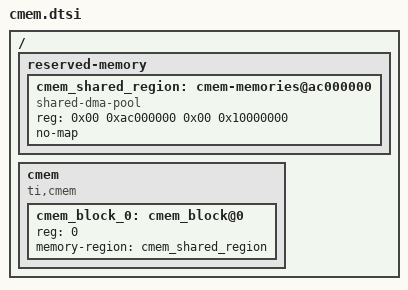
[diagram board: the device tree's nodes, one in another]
/ {
        reserved-memory {
                #address-cells = <2>;
                #size-cells = <2>;
                ranges;

                cmem_shared_region: cmem-memories@ac000000 {
                        compatible="shared-dma-pool";
                        reg = <0x00 0xac000000 0x00 0x10000000>;
                        no-map;
                        status="okay";
                };
        };

        cmem {
                compatible = "ti,cmem";
                #address-cells = <1>;
                #size-cells = <0>;
                status = "okay";
                cmem_block_0:  cmem_block@0 {
                        reg = <0>;
                        memory-region = <&cmem_shared_region>;
                };
        };
};
